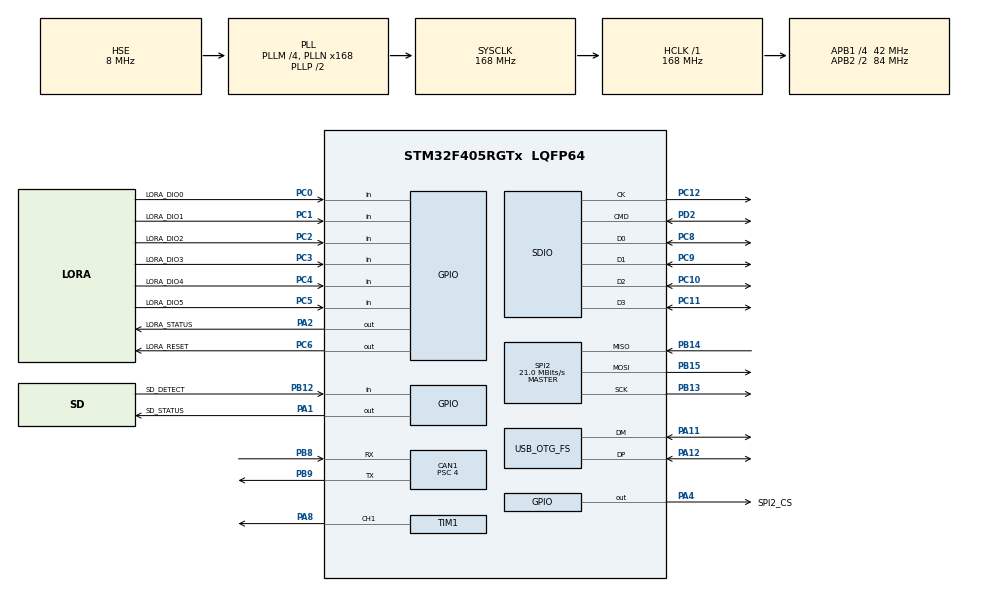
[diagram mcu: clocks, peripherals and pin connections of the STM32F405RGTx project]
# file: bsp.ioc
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CAN1.BS1=CAN_BS1_16TQ
CAN1.BS2=CAN_BS2_4TQ
CAN1.CalculateBaudRate=500000
CAN1.CalculateTimeBit=2000
CAN1.CalculateTimeQuantum=95.23809523809524
CAN1.NART=DISABLE
CAN1.Prescaler=4
CAN1.SJW=CAN_SJW_1TQ
Dma.Request0=SDIO
Dma.SDIO.0.Direction=DMA_PERIPH_TO_MEMORY
Dma.SDIO.0.FIFOMode=DMA_FIFOMODE_ENABLE
Dma.SDIO.0.FIFOThreshold=DMA_FIFO_THRESHOLD_FULL
Dma.SDIO.0.Instance=DMA2_Stream3
Dma.SDIO.0.MemBurst=DMA_MBURST_INC4
Dma.SDIO.0.MemDataAlignment=DMA_MDATAALIGN_WORD
Dma.SDIO.0.MemInc=DMA_MINC_ENABLE
Dma.SDIO.0.Mode=DMA_PFCTRL
Dma.SDIO.0.PeriphBurst=DMA_PBURST_INC4
Dma.SDIO.0.PeriphDataAlignment=DMA_PDATAALIGN_WORD
Dma.SDIO.0.PeriphInc=DMA_PINC_DISABLE
Dma.SDIO.0.Priority=DMA_PRIORITY_LOW
FATFS.BSP.number=1
FATFS._USE_LFN=0
FATFS0.BSP.STBoard=false
FATFS0.BSP.api=Unknown
FATFS0.BSP.instance=PB12
FATFS0.BSP.ip=GPIO
FATFS0.BSP.mode=Input
FATFS0.BSP.name=Detect_SDIO
FATFS0.BSP.solution=PB12
Mcu.Family=STM32F4
Mcu.Name=STM32F405RGTx
Mcu.Package=LQFP64
NVIC.CAN1_RX0_IRQn=true\:0\:0\:false\:false\:true\:true\:true\:true
NVIC.DMA2_Stream3_IRQn=true\:0\:0\:false\:false\:true\:false\:true\:true
NVIC.OTG_FS_IRQn=true\:0\:0\:false\:false\:true\:false\:true\:true
NVIC.PriorityGroup=NVIC_PRIORITYGROUP_4
NVIC.SDIO_IRQn=true\:0\:0\:false\:false\:true\:true\:true\:true
NVIC.TIM6_DAC_IRQn=true\:0\:0\:true\:false\:true\:false\:true\:true
NVIC.TimeBase=TIM6_DAC_IRQn
NVIC.TimeBaseIP=TIM6
PA1.GPIO_Label=SD_STATUS
PA1.Signal=GPIO_Output
PA11.Mode=Device_Only
PA11.Signal=USB_OTG_FS_DM
PA12.Mode=Device_Only
PA12.Signal=USB_OTG_FS_DP
PA13.Mode=Serial_Wire
PA13.Signal=SYS_JTMS-SWDIO
PA14.Mode=Serial_Wire
PA14.Signal=SYS_JTCK-SWCLK
PA2.GPIO_Label=LORA_STATUS
PA2.Signal=GPIO_Output
PA4.GPIO_Label=SPI2_CS
PA4.Signal=GPIO_Output
PA8.Signal=S_TIM1_CH1
PB12.GPIO_Label=SD_DETECT
PB12.Signal=GPIO_Input
PB13.Mode=Full_Duplex_Master
PB13.Signal=SPI2_SCK
PB14.Mode=Full_Duplex_Master
PB14.Signal=SPI2_MISO
PB15.Mode=Full_Duplex_Master
PB15.Signal=SPI2_MOSI
PB8.Mode=CAN_Activate
PB8.Signal=CAN1_RX
PB9.Mode=CAN_Activate
PB9.Signal=CAN1_TX
PC0.GPIO_Label=LORA_DIO0
PC0.Signal=GPIO_Input
PC1.GPIO_Label=LORA_DIO1
PC1.Signal=GPIO_Input
PC10.GPIO_PuPd=GPIO_PULLUP
PC10.Mode=SD_4_bits_Wide_bus
PC10.Signal=SDIO_D2
PC11.GPIO_PuPd=GPIO_PULLUP
PC11.Mode=SD_4_bits_Wide_bus
PC11.Signal=SDIO_D3
PC12.Mode=SD_4_bits_Wide_bus
PC12.Signal=SDIO_CK
PC14-OSC32_IN.Mode=LSE-External-Clock-Source
PC14-OSC32_IN.Signal=RCC_OSC32_IN
PC15-OSC32_OUT.Mode=LSE-External-Clock-Source
PC15-OSC32_OUT.Signal=RCC_OSC32_OUT
PC2.GPIO_Label=LORA_DIO2
PC2.Signal=GPIO_Input
PC3.GPIO_Label=LORA_DIO3
PC3.Signal=GPIO_Input
PC4.GPIO_Label=LORA_DIO4
PC4.Signal=GPIO_Input
PC5.GPIO_Label=LORA_DIO5
PC5.Signal=GPIO_Input
PC6.GPIO_Label=LORA_RESET
PC6.Signal=GPIO_Output
PC8.GPIO_PuPd=GPIO_PULLUP
PC8.Mode=SD_4_bits_Wide_bus
PC8.Signal=SDIO_D0
PC9.GPIO_PuPd=GPIO_PULLUP
PC9.Mode=SD_4_bits_Wide_bus
PC9.Signal=SDIO_D1
PD2.GPIO_PuPd=GPIO_PULLUP
PD2.Mode=SD_4_bits_Wide_bus
PD2.Signal=SDIO_CMD
PH0-OSC_IN.Mode=HSE-External-Oscillator
PH0-OSC_IN.Signal=RCC_OSC_IN
PH1-OSC_OUT.Mode=HSE-External-Oscillator
PH1-OSC_OUT.Signal=RCC_OSC_OUT
ProjectManager.HeapSize=0x200
ProjectManager.StackSize=0x400
ProjectManager.TargetToolchain=Makefile
RCC.48MHZClocksFreq_Value=48000000
RCC.AHBFreq_Value=168000000
RCC.APB1CLKDivider=RCC_HCLK_DIV4
RCC.APB1Freq_Value=42000000
RCC.APB1TimFreq_Value=84000000
RCC.APB2CLKDivider=RCC_HCLK_DIV2
RCC.APB2Freq_Value=84000000
RCC.APB2TimFreq_Value=168000000
RCC.CortexFreq_Value=168000000
RCC.HCLKFreq_Value=168000000
RCC.HSE_VALUE=8000000
RCC.HSI_VALUE=16000000
RCC.LSE_VALUE=32768
RCC.PLLM=4
RCC.PLLN=168
RCC.PLLQ=7
RCC.RCC_RTC_Clock_Source=RCC_RTCCLKSOURCE_LSE
RCC.RCC_RTC_Clock_SourceVirtual=RCC_RTCCLKSOURCE_LSE
RCC.SYSCLKFreq_VALUE=168000000
RCC.SYSCLKSource=RCC_SYSCLKSOURCE_PLLCLK
RCC.VCOOutputFreq_Value=336000000
RTC.Date=7
RTC.Format=RTC_FORMAT_BIN
RTC.Hours=15
RTC.Minutes=40
RTC.Month=RTC_MONTH_FEBRUARY
RTC.WeekDay=RTC_WEEKDAY_SATURDAY
RTC.Year=26
SDIO.ClockDiv=0
SDIO.HardwareFlowControl=SDIO_HARDWARE_FLOW_CONTROL_DISABLE
SH.S_TIM1_CH1.0=TIM1_CH1,PWM Generation1 CH1
SPI2.CalculateBaudRate=21.0 MBits/s
SPI2.Direction=SPI_DIRECTION_2LINES
SPI2.Mode=SPI_MODE_MASTER
SPI2.VirtualType=VM_MASTER
TIM1.Channel-PWM\ Generation1\ CH1=TIM_CHANNEL_1
TIM1.Period=20000-1
TIM1.Prescaler=168-1
USB_DEVICE.CLASS_NAME_FS=CDC
USB_DEVICE.VirtualMode-CDC_FS=Cdc
USB_DEVICE.VirtualModeFS=Cdc_FS
USB_OTG_FS.VirtualMode=Device_Only
VP_FATFS_VS_SDIO.Mode=SDIO
VP_RTC_VS_RTC_Activate.Mode=RTC_Enabled
VP_RTC_VS_RTC_Calendar.Mode=RTC_Calendar
VP_SYS_VS_tim6.Mode=TIM6
VP_TIM1_VS_ClockSourceINT.Mode=Internal
VP_USB_DEVICE_VS_USB_DEVICE_CDC_FS.Mode=CDC_FS
board=custom

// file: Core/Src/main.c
/* USER CODE BEGIN Header */
/**
 ******************************************************************************
 * @file           : main.c
 * @brief          : Main program body
 ******************************************************************************
 * @attention
 *
 * Copyright (c) 2026 STMicroelectronics.
 * All rights reserved.
 *
 * This software is licensed under terms that can be found in the LICENSE file
 * in the root directory of this software component.
 * If no LICENSE file comes with this software, it is provided AS-IS.
 *
 ******************************************************************************
 */
/* USER CODE END Header */
#include "main.h"

#include "fatfs.h"
#include "usb_device.h"

/* USER CODE BEGIN Includes */
#include <string.h>

#include "../../USB_DEVICE/App/usbd_cdc_if.h"

/* USER CODE END Includes */

CAN_HandleTypeDef hcan1;

RTC_HandleTypeDef hrtc;

SD_HandleTypeDef hsd;
DMA_HandleTypeDef hdma_sdio;

SPI_HandleTypeDef hspi2;

TIM_HandleTypeDef htim1;

void SystemClock_Config(void);
static void MX_GPIO_Init(void);
static void MX_DMA_Init(void);
static void MX_CAN1_Init(void);
static void MX_RTC_Init(void);
static void MX_SDIO_SD_Init(void);
static void MX_SPI2_Init(void);
static void MX_TIM1_Init(void);

void BspInit(void) {

  /* MCU Configuration--------------------------------------------------------*/

  /* Reset of all peripherals, Initializes the Flash interface and the Systick. */
  HAL_Init();

  /* Configure the system clock */
  SystemClock_Config();

  /* Initialize all configured peripherals */
  MX_GPIO_Init();
  MX_DMA_Init();
  MX_CAN1_Init();
  MX_RTC_Init();
  MX_SDIO_SD_Init();
  MX_SPI2_Init();
  MX_USB_DEVICE_Init();
  MX_FATFS_Init();
  MX_TIM1_Init();

  /* Infinite loop */
  /* USER CODE BEGIN WHILE */
  // while (1) {
  // 1. Blink the LED so we know the board is alive
  //	          HAL_GPIO_TogglePin(LORA_LED_GPIO_Port, LORA_LED_Pin);

  // 2. Define the message
  // const char* msg = "Hello World\r\n";

  // 3. Transmit over USB
  // CDC_Transmit_FS takes a uint8_t pointer and the length of the data
  // CDC_Transmit_FS((uint8_t*)msg, strlen(msg));

  // 4. Wait
  // HAL_Delay(1000);
  /* USER CODE END WHILE */

  /* USER CODE BEGIN 3 */
  // }
  /* USER CODE END 3 */
}

void SystemClock_Config(void) {
  RCC_OscInitTypeDef RCC_OscInitStruct = {0};
  RCC_ClkInitTypeDef RCC_ClkInitStruct = {0};

  /** Configure the main internal regulator output voltage
   */
  __HAL_RCC_PWR_CLK_ENABLE();
  __HAL_PWR_VOLTAGESCALING_CONFIG(PWR_REGULATOR_VOLTAGE_SCALE1);

  /** Initializes the RCC Oscillators according to the specified parameters
   * in the RCC_OscInitTypeDef structure.
   */
  RCC_OscInitStruct.OscillatorType = RCC_OSCILLATORTYPE_HSE | RCC_OSCILLATORTYPE_LSE;
  RCC_OscInitStruct.HSEState = RCC_HSE_ON;
  RCC_OscInitStruct.LSEState = RCC_LSE_BYPASS;
  RCC_OscInitStruct.PLL.PLLState = RCC_PLL_ON;
  RCC_OscInitStruct.PLL.PLLSource = RCC_PLLSOURCE_HSE;
  RCC_OscInitStruct.PLL.PLLM = 4;
  RCC_OscInitStruct.PLL.PLLN = 168;
  RCC_OscInitStruct.PLL.PLLP = RCC_PLLP_DIV2;
  RCC_OscInitStruct.PLL.PLLQ = 7;
  if (HAL_RCC_OscConfig(&RCC_OscInitStruct) != HAL_OK) {
    Error_Handler();
  }

  /** Initializes the CPU, AHB and APB buses clocks
   */
  RCC_ClkInitStruct.ClockType =
      RCC_CLOCKTYPE_HCLK | RCC_CLOCKTYPE_SYSCLK | RCC_CLOCKTYPE_PCLK1 | RCC_CLOCKTYPE_PCLK2;
  RCC_ClkInitStruct.SYSCLKSource = RCC_SYSCLKSOURCE_PLLCLK;
  RCC_ClkInitStruct.AHBCLKDivider = RCC_SYSCLK_DIV1;
  RCC_ClkInitStruct.APB1CLKDivider = RCC_HCLK_DIV4;
  RCC_ClkInitStruct.APB2CLKDivider = RCC_HCLK_DIV2;

  if (HAL_RCC_ClockConfig(&RCC_ClkInitStruct, FLASH_LATENCY_5) != HAL_OK) {
    Error_Handler();
  }
}

static void MX_CAN1_Init(void) {
  /* USER CODE BEGIN CAN1_Init 0 */
  //
  /* USER CODE END CAN1_Init 0 */

  /* USER CODE BEGIN CAN1_Init 1 */
  //
  /* USER CODE END CAN1_Init 1 */
  hcan1.Instance = CAN1;
  hcan1.Init.Prescaler = 4;
  hcan1.Init.Mode = CAN_MODE_NORMAL;
  hcan1.Init.SyncJumpWidth = CAN_SJW_1TQ;
  hcan1.Init.TimeSeg1 = CAN_BS1_16TQ;
  hcan1.Init.TimeSeg2 = CAN_BS2_4TQ;
  hcan1.Init.TimeTriggeredMode = DISABLE;
  hcan1.Init.AutoBusOff = DISABLE;
  hcan1.Init.AutoWakeUp = DISABLE;
  hcan1.Init.AutoRetransmission = DISABLE;
  hcan1.Init.ReceiveFifoLocked = DISABLE;
  hcan1.Init.TransmitFifoPriority = DISABLE;
  if (HAL_CAN_Init(&hcan1) != HAL_OK) {
    Error_Handler();
  }
  /* USER CODE BEGIN CAN1_Init 2 */
  //
  /* USER CODE END CAN1_Init 2 */
}

static void MX_RTC_Init(void) {
  // /* USER CODE BEGIN RTC_Init 0 */
  // //
  // /* USER CODE END RTC_Init 0 */

  //  RTC_TimeTypeDef sTime = {0};
  //  RTC_DateTypeDef sDate = {0};

  // /* USER CODE BEGIN RTC_Init 1 */
  // //
  // /* USER CODE END RTC_Init 1 */

  // /** Initialize RTC Only
  //  */
  //  hrtc.Instance = RTC;
  //  hrtc.Init.HourFormat = RTC_HOURFORMAT_24;
  //  hrtc.Init.AsynchPrediv = 127;
  //  hrtc.Init.SynchPrediv = 255;
  //  hrtc.Init.OutPut = RTC_OUTPUT_DISABLE;
  //  hrtc.Init.OutPutPolarity = RTC_OUTPUT_POLARITY_HIGH;
  //  hrtc.Init.OutPutType = RTC_OUTPUT_TYPE_OPENDRAIN;
  //  if (HAL_RTC_Init(&hrtc) != HAL_OK) {
  //   Error_Handler();
  // }

  // /* USER CODE BEGIN Check_RTC_BKUP */
  // //
  // /* USER CODE END Check_RTC_BKUP */

  // /** Initialize RTC and set the Time and Date
  //  */
  //  sTime.Hours = 15;
  //  sTime.Minutes = 40;
  //  sTime.Seconds = 0;
  //  sTime.DayLightSaving = RTC_DAYLIGHTSAVING_NONE;
  //  sTime.StoreOperation = RTC_STOREOPERATION_RESET;
  //  if (HAL_RTC_SetTime(&hrtc, &sTime, RTC_FORMAT_BIN) != HAL_OK) {
  //   Error_Handler();
  // }
  //  sDate.WeekDay = RTC_WEEKDAY_SATURDAY;
  //  sDate.Month = RTC_MONTH_FEBRUARY;
  //  sDate.Date = 7;
  //  sDate.Year = 26;

  //  if (HAL_RTC_SetDate(&hrtc, &sDate, RTC_FORMAT_BIN) != HAL_OK) {
  //    Error_Handler();
  //  }
  // /* USER CODE BEGIN RTC_Init 2 */
  // //
  // /* USER CODE END RTC_Init 2 */
}

static void MX_SDIO_SD_Init(void) {

  hsd.Instance = SDIO;
  hsd.Init.ClockEdge = SDIO_CLOCK_EDGE_RISING;
  hsd.Init.ClockBypass = SDIO_CLOCK_BYPASS_DISABLE;
  hsd.Init.ClockPowerSave = SDIO_CLOCK_POWER_SAVE_DISABLE;
  hsd.Init.BusWide = SDIO_BUS_WIDE_1B;
  hsd.Init.HardwareFlowControl = SDIO_HARDWARE_FLOW_CONTROL_DISABLE;
  hsd.Init.ClockDiv = 0;
}

static void MX_SPI2_Init(void) {

  /* SPI2 parameter configuration*/
  hspi2.Instance = SPI2;
  hspi2.Init.Mode = SPI_MODE_MASTER;
  hspi2.Init.Direction = SPI_DIRECTION_2LINES;
  hspi2.Init.DataSize = SPI_DATASIZE_8BIT;
  hspi2.Init.CLKPolarity = SPI_POLARITY_LOW;
  hspi2.Init.CLKPhase = SPI_PHASE_1EDGE;
  hspi2.Init.NSS = SPI_NSS_SOFT;
  hspi2.Init.BaudRatePrescaler = SPI_BAUDRATEPRESCALER_2;
  hspi2.Init.FirstBit = SPI_FIRSTBIT_MSB;
  hspi2.Init.TIMode = SPI_TIMODE_DISABLE;
  hspi2.Init.CRCCalculation = SPI_CRCCALCULATION_DISABLE;
  hspi2.Init.CRCPolynomial = 10;
  if (HAL_SPI_Init(&hspi2) != HAL_OK) {
    Error_Handler();
  }
}

static void MX_TIM1_Init(void) {

  TIM_ClockConfigTypeDef sClockSourceConfig = {0};
  TIM_MasterConfigTypeDef sMasterConfig = {0};
  TIM_OC_InitTypeDef sConfigOC = {0};
  TIM_BreakDeadTimeConfigTypeDef sBreakDeadTimeConfig = {0};

  htim1.Instance = TIM1;
  htim1.Init.Prescaler = 167;
  htim1.Init.CounterMode = TIM_COUNTERMODE_UP;
  htim1.Init.Period = 19999;
  htim1.Init.ClockDivision = TIM_CLOCKDIVISION_DIV1;
  htim1.Init.RepetitionCounter = 0;
  htim1.Init.AutoReloadPreload = TIM_AUTORELOAD_PRELOAD_DISABLE;
  if (HAL_TIM_Base_Init(&htim1) != HAL_OK) {
    Error_Handler();
  }
  sClockSourceConfig.ClockSource = TIM_CLOCKSOURCE_INTERNAL;
  if (HAL_TIM_ConfigClockSource(&htim1, &sClockSourceConfig) != HAL_OK) {
    Error_Handler();
  }
  if (HAL_TIM_PWM_Init(&htim1) != HAL_OK) {
    Error_Handler();
  }
  sMasterConfig.MasterOutputTrigger = TIM_TRGO_RESET;
  sMasterConfig.MasterSlaveMode = TIM_MASTERSLAVEMODE_DISABLE;
  if (HAL_TIMEx_MasterConfigSynchronization(&htim1, &sMasterConfig) != HAL_OK) {
    Error_Handler();
  }
  sConfigOC.OCMode = TIM_OCMODE_PWM1;
  sConfigOC.Pulse = 0;
  sConfigOC.OCPolarity = TIM_OCPOLARITY_HIGH;
  sConfigOC.OCNPolarity = TIM_OCNPOLARITY_HIGH;
  sConfigOC.OCFastMode = TIM_OCFAST_DISABLE;
  sConfigOC.OCIdleState = TIM_OCIDLESTATE_RESET;
  sConfigOC.OCNIdleState = TIM_OCNIDLESTATE_RESET;
  if (HAL_TIM_PWM_ConfigChannel(&htim1, &sConfigOC, TIM_CHANNEL_1) != HAL_OK) {
    Error_Handler();
  }
  sBreakDeadTimeConfig.OffStateRunMode = TIM_OSSR_DISABLE;
  sBreakDeadTimeConfig.OffStateIDLEMode = TIM_OSSI_DISABLE;
  sBreakDeadTimeConfig.LockLevel = TIM_LOCKLEVEL_OFF;
  sBreakDeadTimeConfig.DeadTime = 0;
  sBreakDeadTimeConfig.BreakState = TIM_BREAK_DISABLE;
  sBreakDeadTimeConfig.BreakPolarity = TIM_BREAKPOLARITY_HIGH;
  sBreakDeadTimeConfig.AutomaticOutput = TIM_AUTOMATICOUTPUT_DISABLE;
  if (HAL_TIMEx_ConfigBreakDeadTime(&htim1, &sBreakDeadTimeConfig) != HAL_OK) {
    Error_Handler();
  }
  HAL_TIM_MspPostInit(&htim1);
}

static void MX_DMA_Init(void) {
  /* DMA controller clock enable */
  __HAL_RCC_DMA2_CLK_ENABLE();

  /* DMA interrupt init */
  /* DMA2_Stream3_IRQn interrupt configuration */
  HAL_NVIC_SetPriority(DMA2_Stream3_IRQn, 0, 0);
  HAL_NVIC_EnableIRQ(DMA2_Stream3_IRQn);
}

static void MX_GPIO_Init(void) {
  GPIO_InitTypeDef GPIO_InitStruct = {0};

  /* GPIO Ports Clock Enable */
  __HAL_RCC_GPIOC_CLK_ENABLE();
  __HAL_RCC_GPIOH_CLK_ENABLE();
  __HAL_RCC_GPIOA_CLK_ENABLE();
  __HAL_RCC_GPIOB_CLK_ENABLE();
  __HAL_RCC_GPIOD_CLK_ENABLE();

  /*Configure GPIO pin Output Level */
  HAL_GPIO_WritePin(GPIOA, SD_STATUS_Pin | LORA_STATUS_Pin | SPI2_CS_Pin, GPIO_PIN_RESET);

  /*Configure GPIO pin Output Level */
  HAL_GPIO_WritePin(LORA_RESET_GPIO_Port, LORA_RESET_Pin, GPIO_PIN_RESET);

  /*Configure GPIO pins : LORA_DIO0_Pin LORA_DIO1_Pin LORA_DIO2_Pin LORA_DIO3_Pin
                           LORA_DIO4_Pin LORA_DIO5_Pin */
  GPIO_InitStruct.Pin =
      LORA_DIO0_Pin | LORA_DIO1_Pin | LORA_DIO2_Pin | LORA_DIO3_Pin | LORA_DIO4_Pin | LORA_DIO5_Pin;
  GPIO_InitStruct.Mode = GPIO_MODE_INPUT;
  GPIO_InitStruct.Pull = GPIO_NOPULL;
  HAL_GPIO_Init(GPIOC, &GPIO_InitStruct);

  /*Configure GPIO pins : SD_STATUS_Pin LORA_STATUS_Pin SPI2_CS_Pin */
  GPIO_InitStruct.Pin = SD_STATUS_Pin | LORA_STATUS_Pin | SPI2_CS_Pin;
  GPIO_InitStruct.Mode = GPIO_MODE_OUTPUT_PP;
  GPIO_InitStruct.Pull = GPIO_NOPULL;
  GPIO_InitStruct.Speed = GPIO_SPEED_FREQ_LOW;
  HAL_GPIO_Init(GPIOA, &GPIO_InitStruct);

  /*Configure GPIO pin : SD_DETECT_Pin */
  GPIO_InitStruct.Pin = SD_DETECT_Pin;
  GPIO_InitStruct.Mode = GPIO_MODE_INPUT;
  GPIO_InitStruct.Pull = GPIO_NOPULL;
  HAL_GPIO_Init(SD_DETECT_GPIO_Port, &GPIO_InitStruct);

  /*Configure GPIO pin : LORA_RESET_Pin */
  GPIO_InitStruct.Pin = LORA_RESET_Pin;
  GPIO_InitStruct.Mode = GPIO_MODE_OUTPUT_PP;
  GPIO_InitStruct.Pull = GPIO_NOPULL;
  GPIO_InitStruct.Speed = GPIO_SPEED_FREQ_LOW;
  HAL_GPIO_Init(LORA_RESET_GPIO_Port, &GPIO_InitStruct);

}

void HAL_TIM_PeriodElapsedCallback(TIM_HandleTypeDef* htim) {
  if (htim->Instance == TIM6) {
    HAL_IncTick();
  }
}

void Error_Handler(void) {
  __disable_irq();
  while (1) {
  }
}
